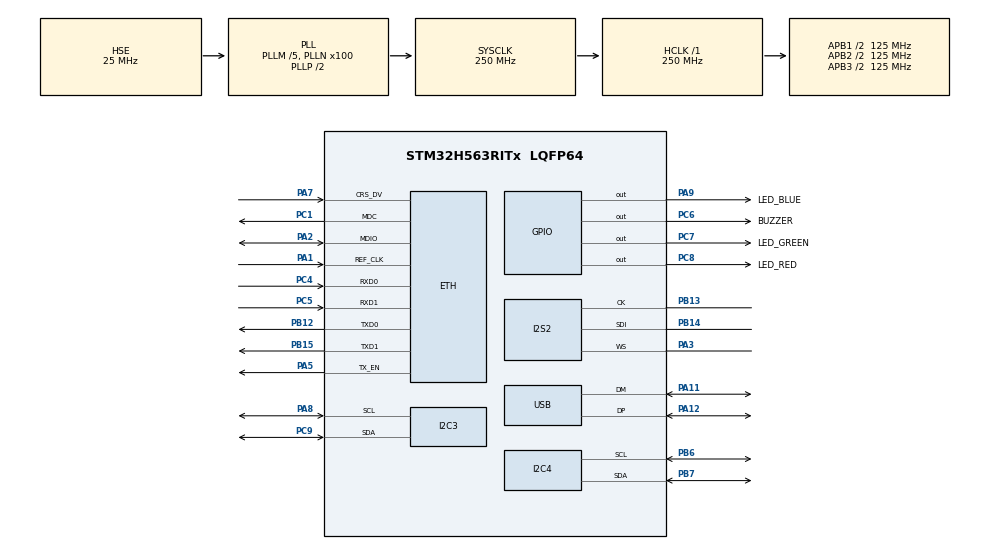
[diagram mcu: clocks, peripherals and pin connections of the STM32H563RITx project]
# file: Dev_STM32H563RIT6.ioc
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BOOTPATH.BootPathName=LEGACY
BOOTPATH.UserSelectedBootPath=LEGACY
CORTEX_M33_NS.userName=CORTEX_M33
ETH.MediaInterface=HAL_ETH_RMII_MODE
GPDMA1.CIRCULARMODE_GPDMACH0=ENABLE
GPDMA1.DESTDATAWIDTH_GPDMACH0=DMA_DEST_DATAWIDTH_HALFWORD
GPDMA1.DESTINC_GPDMACH0=DMA_DINC_INCREMENTED
GPDMA1.IPHANDLE_GPDMACH0-SIMPLEREQUEST_GPDMACH0=__NULL
GPDMA1.REQUEST_GPDMACH0=GPDMA1_REQUEST_SPI2_RX
GPDMA1.SRCDATAWIDTH_GPDMACH0=DMA_SRC_DATAWIDTH_HALFWORD
GPDMA1.SRCINC_GPDMACH0=DMA_SINC_FIXED
GPDMA1.TRANSFERALLOCATEDPORTDEST_GPDMACH0=DMA_DEST_ALLOCATED_PORT1
I2C3.Timing=0x20A0A3F6
I2C4.Timing=0x20A0A3F6
I2S2.AudioFreq=I2S_AUDIOFREQ_32K
I2S2.DataFormat=I2S_DATAFORMAT_16B_EXTENDED
I2S2.ErrorAudioFreq=0.05 %
I2S2.Instance=SPI$Index
I2S2.RealAudioFreq=32.018 KHz
Mcu.Family=STM32H5
Mcu.Name=STM32H563RITx
Mcu.Package=LQFP64
NETXDUO.ETH_ON=1
NETXDUO.LAN_8742=1
NETXDUO.NX_APP_MEM_POOL_SIZE=1024*100
NETXDUO.NX_APP_THREAD_STACK_SIZE=1024*4
NETXDUO.NX_DISABLE_UDP_TX_CHECKSUM=false
NETXDUO.NetXDuo_Application_Thread_Name=nx_UDP_thread_entry
NETXDUO.NetXDuo_Generate_Init_Code=true
NETXDUO.NetXDuo_Static_IP_address=192.168.1.111
NVIC.ETH_IRQn=true\:0\:0\:false\:false\:true\:false\:true\:true\:true
NVIC.GPDMA1_Channel0_IRQn=true\:0\:0\:false\:false\:true\:false\:false\:true\:true
NVIC.PriorityGroup=NVIC_PRIORITYGROUP_4
NVIC.TIM6_IRQn=true\:15\:0\:false\:false\:true\:false\:false\:true\:true
NVIC.TimeBase=TIM6_IRQn
NVIC.TimeBaseIP=TIM6
NetXDuo.BSP.number=1
NetXDuo0.BSP.STBoard=false
NetXDuo0.BSP.api=BSP_COMPONENT_DRIVER
NetXDuo0.BSP.component=lan8742
NetXDuo0.BSP.instance=lan8742
NetXDuo0.BSP.name=LAN_Component
NetXDuo0.BSP.semaphore=SEMA_lan8742
NetXDuo0.BSP.solution=lan8742
PA1.GPIO_Speed_Default_HIGH=GPIO_SPEED_FREQ_VERY_HIGH
PA1.Mode=RMII
PA1.Signal=ETH_REF_CLK
PA11.Mode=Device
PA11.Signal=USB_DM
PA12.Mode=Device
PA12.Signal=USB_DP
PA13(JTMS/SWDIO).Mode=Serial_Wire
PA13(JTMS/SWDIO).Signal=DEBUG_JTMS-SWDIO
PA14(JTCK/SWCLK).Mode=Serial_Wire
PA14(JTCK/SWCLK).Signal=DEBUG_JTCK-SWCLK
PA2.GPIO_Speed_Default_HIGH=GPIO_SPEED_FREQ_VERY_HIGH
PA2.Mode=RMII
PA2.Signal=ETH_MDIO
PA3.GPIO_Speed=GPIO_SPEED_FREQ_VERY_HIGH
PA3.Mode=Half_Duplex_Master_Rx
PA3.Signal=I2S2_WS
PA5.GPIO_Speed_Default_HIGH=GPIO_SPEED_FREQ_VERY_HIGH
PA5.Mode=RMII
PA5.Signal=ETH_TX_EN
PA7.GPIO_Speed_Default_HIGH=GPIO_SPEED_FREQ_VERY_HIGH
PA7.Mode=RMII
PA7.Signal=ETH_CRS_DV
PA8.Mode=I2C
PA8.Signal=I2C3_SCL
PA9.GPIO_Label=LED_BLUE
PA9.Signal=GPIO_Output
PB12.GPIO_Speed_Default_HIGH=GPIO_SPEED_FREQ_VERY_HIGH
PB12.Mode=RMII
PB12.Signal=ETH_TXD0
PB13.GPIO_Speed=GPIO_SPEED_FREQ_VERY_HIGH
PB13.Mode=Half_Duplex_Master_Rx
PB13.Signal=I2S2_CK
PB14.GPIO_Speed=GPIO_SPEED_FREQ_VERY_HIGH
PB14.Mode=Half_Duplex_Master_Rx
PB14.Signal=I2S2_SDI
PB15.GPIO_Speed_Default_HIGH=GPIO_SPEED_FREQ_VERY_HIGH
PB15.Mode=RMII
PB15.Signal=ETH_TXD1
PB6.Mode=I2C
PB6.Signal=I2C4_SCL
PB7.Mode=I2C
PB7.Signal=I2C4_SDA
PC1.GPIO_Speed_Default_HIGH=GPIO_SPEED_FREQ_VERY_HIGH
PC1.Mode=RMII
PC1.Signal=ETH_MDC
PC4.GPIO_Speed_Default_HIGH=GPIO_SPEED_FREQ_VERY_HIGH
PC4.Mode=RMII
PC4.Signal=ETH_RXD0
PC5.GPIO_Speed_Default_HIGH=GPIO_SPEED_FREQ_VERY_HIGH
PC5.Mode=RMII
PC5.Signal=ETH_RXD1
PC6.GPIO_Label=BUZZER
PC6.Signal=GPIO_Output
PC7.GPIO_Label=LED_GREEN
PC7.Signal=GPIO_Output
PC8.GPIO_Label=LED_RED
PC8.Signal=GPIO_Output
PC9.Mode=I2C
PC9.Signal=I2C3_SDA
PH0-OSC_IN(PH0).Mode=HSE-External-Oscillator
PH0-OSC_IN(PH0).Signal=RCC_OSC_IN
PH1-OSC_OUT(PH1).Mode=HSE-External-Oscillator
PH1-OSC_OUT(PH1).Signal=RCC_OSC_OUT
ProjectManager.HeapSize=0x200
ProjectManager.StackSize=0x400
ProjectManager.TargetToolchain=CMake
RCC.ADCFreq_Value=250000000
RCC.AHBFreq_Value=250000000
RCC.APB1CLKDivider=RCC_HCLK_DIV2
RCC.APB1Freq_Value=125000000
RCC.APB1TimFreq_Value=250000000
RCC.APB2CLKDivider=RCC_HCLK_DIV2
RCC.APB2Freq_Value=125000000
RCC.APB2TimFreq_Value=250000000
RCC.APB3CLKDivider=RCC_HCLK_DIV2
RCC.APB3Freq_Value=125000000
RCC.CSI_VALUE=4000000
RCC.CortexFreq_Value=250000000
RCC.EPOD_VALUE=25000000
RCC.HCLKFreq_Value=250000000
RCC.HSE_VALUE=25000000
RCC.HSI48_VALUE=48000000
RCC.HSI_VALUE=64000000
RCC.LSE_VALUE=32768
RCC.LSIRC_VALUE=32000
RCC.PLLM=5
RCC.PLLN=100
RCC.PLLSourceVirtual=RCC_PLL1_SOURCE_HSE
RCC.SYSCLKFreq_VALUE=250000000
RCC.SYSCLKSource=RCC_SYSCLKSOURCE_PLLCLK
RCC.USBFreq_Value=48000000
RCC.VCOOutputFreq_Value=500000000
THREADX.TX_APP_CREATION=1
THREADX.TX_APP_GENERATE_INIT_CODE=true
THREADX.TX_APP_MEM_POOL_SIZE=1024*20
THREADX.TX_APP_STACK_SIZE=1024*10
THREADX.TX_APP_THREAD_ENTRY=tx_I2C_thread_entry
THREADX.TX_APP_THREAD_NAME=tx I2C thread
USB.VirtualMode=Device_Only
VP_BOOTPATH_VS_BOOTPATH.Mode=BP_Activate
VP_CORTEX_M33_NS_VS_Hclk.Mode=Hclk_Mode
VP_GPDMA1_VS_GPDMACH0.Mode=SIMPLEREQUEST_GPDMACH0
VP_ICACHE_VS_ICACHE.Mode=DirectMappedCache
VP_MEMORYMAP_VS_MEMORYMAP.Mode=CurAppReg
VP_NETXDUO_VS_EthernetOoPhyOoInterface.Mode=LAN8742_Phy_Interface
VP_NETXDUO_VS_NXOoCore.Mode=NX_Core
VP_NETXDUO_VS_NetworkOoInterface.Mode=Ethernet_Interface
VP_PWR_VS_DBSignals.Mode=DisableDeadBatterySignals
VP_PWR_VS_LPOM.Mode=PowerOptimisation
VP_PWR_VS_SECSignals.Mode=Security/Privilege
VP_SYS_VS_tim6.Mode=TIM6
VP_THREADX_VS_RTOSJjThreadXJjCoreJjDefault.Mode=Core_Default
board=custom

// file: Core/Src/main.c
/* USER CODE BEGIN Header */
/**
  ******************************************************************************
  * @file           : main.c
  * @brief          : Main program body
  ******************************************************************************
  * @attention
  *
  * Copyright (c) 2025 STMicroelectronics.
  * All rights reserved.
  *
  * This software is licensed under terms that can be found in the LICENSE file
  * in the root directory of this software component.
  * If no LICENSE file comes with this software, it is provided AS-IS.
  *
  ******************************************************************************
  */
/* USER CODE END Header */
#include "app_threadx.h"
#include "main.h"
#include "string.h"

/* USER CODE BEGIN Includes */
#include <stdio.h>
#include "app_netxduo.h"
#include "string.h"
/* USER CODE END Includes */

/* USER CODE BEGIN PTD */
//extern void blink_blue(void);
/* USER CODE END PTD */

ETH_DMADescTypeDef  DMARxDscrTab[ETH_RX_DESC_CNT]; /* Ethernet Rx DMA Descriptors */
ETH_DMADescTypeDef  DMATxDscrTab[ETH_TX_DESC_CNT]; /* Ethernet Tx DMA Descriptors */

ETH_HandleTypeDef heth;

I2C_HandleTypeDef hi2c3;
I2C_HandleTypeDef hi2c4;

I2S_HandleTypeDef hi2s2;
DMA_NodeTypeDef Node_GPDMA1_Channel0;
DMA_QListTypeDef List_GPDMA1_Channel0;
DMA_HandleTypeDef handle_GPDMA1_Channel0;

PCD_HandleTypeDef hpcd_USB_DRD_FS;

void SystemClock_Config(void);
static void MX_GPIO_Init(void);
static void MX_GPDMA1_Init(void);
static void MX_ETH_Init(void);
static void MX_I2C3_Init(void);
static void MX_I2C4_Init(void);
static void MX_I2S2_Init(void);
static void MX_ICACHE_Init(void);
static void MX_USB_PCD_Init(void);

int main(void)
{

  /* MCU Configuration--------------------------------------------------------*/

  /* Reset of all peripherals, Initializes the Flash interface and the Systick. */
  HAL_Init();

  /* Configure the system clock */
  SystemClock_Config();

  /* Initialize all configured peripherals */
  MX_GPIO_Init();
  MX_GPDMA1_Init();
  MX_ETH_Init();
  MX_I2C3_Init();
  MX_I2C4_Init();
  MX_I2S2_Init();
  MX_ICACHE_Init();
  MX_USB_PCD_Init();

  MX_ThreadX_Init();

  /* We should never get here as control is now taken by the scheduler */

  /* Infinite loop */
  while (1)
  {

  }
}

void SystemClock_Config(void)
{
  RCC_OscInitTypeDef RCC_OscInitStruct = {0};
  RCC_ClkInitTypeDef RCC_ClkInitStruct = {0};

  /** Configure the main internal regulator output voltage
  */
  __HAL_PWR_VOLTAGESCALING_CONFIG(PWR_REGULATOR_VOLTAGE_SCALE0);

  while(!__HAL_PWR_GET_FLAG(PWR_FLAG_VOSRDY)) {}

  /** Initializes the RCC Oscillators according to the specified parameters
  * in the RCC_OscInitTypeDef structure.
  */
  RCC_OscInitStruct.OscillatorType = RCC_OSCILLATORTYPE_HSI48|RCC_OSCILLATORTYPE_HSE;
  RCC_OscInitStruct.HSEState = RCC_HSE_ON;
  RCC_OscInitStruct.HSI48State = RCC_HSI48_ON;
  RCC_OscInitStruct.PLL.PLLState = RCC_PLL_ON;
  RCC_OscInitStruct.PLL.PLLSource = RCC_PLL1_SOURCE_HSE;
  RCC_OscInitStruct.PLL.PLLM = 5;
  RCC_OscInitStruct.PLL.PLLN = 100;
  RCC_OscInitStruct.PLL.PLLP = 2;
  RCC_OscInitStruct.PLL.PLLQ = 2;
  RCC_OscInitStruct.PLL.PLLR = 2;
  RCC_OscInitStruct.PLL.PLLRGE = RCC_PLL1_VCIRANGE_2;
  RCC_OscInitStruct.PLL.PLLVCOSEL = RCC_PLL1_VCORANGE_WIDE;
  RCC_OscInitStruct.PLL.PLLFRACN = 0;
  if (HAL_RCC_OscConfig(&RCC_OscInitStruct) != HAL_OK)
  {
    Error_Handler();
  }

  /** Initializes the CPU, AHB and APB buses clocks
  */
  RCC_ClkInitStruct.ClockType = RCC_CLOCKTYPE_HCLK|RCC_CLOCKTYPE_SYSCLK
                              |RCC_CLOCKTYPE_PCLK1|RCC_CLOCKTYPE_PCLK2
                              |RCC_CLOCKTYPE_PCLK3;
  RCC_ClkInitStruct.SYSCLKSource = RCC_SYSCLKSOURCE_PLLCLK;
  RCC_ClkInitStruct.AHBCLKDivider = RCC_SYSCLK_DIV1;
  RCC_ClkInitStruct.APB1CLKDivider = RCC_HCLK_DIV2;
  RCC_ClkInitStruct.APB2CLKDivider = RCC_HCLK_DIV2;
  RCC_ClkInitStruct.APB3CLKDivider = RCC_HCLK_DIV2;

  if (HAL_RCC_ClockConfig(&RCC_ClkInitStruct, FLASH_LATENCY_5) != HAL_OK)
  {
    Error_Handler();
  }

  /** Configure the programming delay
  */
  __HAL_FLASH_SET_PROGRAM_DELAY(FLASH_PROGRAMMING_DELAY_2);
}

static void MX_ETH_Init(void)
{

   static uint8_t MACAddr[6];

  /* USER CODE BEGIN ETH_Init 1 */
      // for(int i = 0;i < 5; i++){
      //   blink_blue();
      // }
  /* USER CODE END ETH_Init 1 */
  heth.Instance = ETH;
  MACAddr[0] = 0x00;
  MACAddr[1] = 0x80;
  MACAddr[2] = 0xE1;
  MACAddr[3] = 0x00;
  MACAddr[4] = 0x00;
  MACAddr[5] = 0x00;
  heth.Init.MACAddr = &MACAddr[0];
  heth.Init.MediaInterface = HAL_ETH_RMII_MODE;
  heth.Init.TxDesc = DMATxDscrTab;
  heth.Init.RxDesc = DMARxDscrTab;
  heth.Init.RxBuffLen = 1524;

  if (HAL_ETH_Init(&heth) != HAL_OK)
  {
    Error_Handler();
  }

}

static void MX_GPDMA1_Init(void)
{

  /* Peripheral clock enable */
  __HAL_RCC_GPDMA1_CLK_ENABLE();

  /* GPDMA1 interrupt Init */
    HAL_NVIC_SetPriority(GPDMA1_Channel0_IRQn, 0, 0);
    HAL_NVIC_EnableIRQ(GPDMA1_Channel0_IRQn);

}

static void MX_I2C3_Init(void)
{

  hi2c3.Instance = I2C3;
  hi2c3.Init.Timing = 0x20A0A3F6;
  hi2c3.Init.OwnAddress1 = 0;
  hi2c3.Init.AddressingMode = I2C_ADDRESSINGMODE_7BIT;
  hi2c3.Init.DualAddressMode = I2C_DUALADDRESS_DISABLE;
  hi2c3.Init.OwnAddress2 = 0;
  hi2c3.Init.OwnAddress2Masks = I2C_OA2_NOMASK;
  hi2c3.Init.GeneralCallMode = I2C_GENERALCALL_DISABLE;
  hi2c3.Init.NoStretchMode = I2C_NOSTRETCH_DISABLE;
  if (HAL_I2C_Init(&hi2c3) != HAL_OK)
  {
    Error_Handler();
  }

  /** Configure Analogue filter
  */
  if (HAL_I2CEx_ConfigAnalogFilter(&hi2c3, I2C_ANALOGFILTER_ENABLE) != HAL_OK)
  {
    Error_Handler();
  }

  /** Configure Digital filter
  */
  if (HAL_I2CEx_ConfigDigitalFilter(&hi2c3, 0) != HAL_OK)
  {
    Error_Handler();
  }

}

static void MX_I2C4_Init(void)
{

  hi2c4.Instance = I2C4;
  hi2c4.Init.Timing = 0x20A0A3F6;
  hi2c4.Init.OwnAddress1 = 0;
  hi2c4.Init.AddressingMode = I2C_ADDRESSINGMODE_7BIT;
  hi2c4.Init.DualAddressMode = I2C_DUALADDRESS_DISABLE;
  hi2c4.Init.OwnAddress2 = 0;
  hi2c4.Init.OwnAddress2Masks = I2C_OA2_NOMASK;
  hi2c4.Init.GeneralCallMode = I2C_GENERALCALL_DISABLE;
  hi2c4.Init.NoStretchMode = I2C_NOSTRETCH_DISABLE;
  if (HAL_I2C_Init(&hi2c4) != HAL_OK)
  {
    Error_Handler();
  }

  /** Configure Analogue filter
  */
  if (HAL_I2CEx_ConfigAnalogFilter(&hi2c4, I2C_ANALOGFILTER_ENABLE) != HAL_OK)
  {
    Error_Handler();
  }

  /** Configure Digital filter
  */
  if (HAL_I2CEx_ConfigDigitalFilter(&hi2c4, 0) != HAL_OK)
  {
    Error_Handler();
  }

}

static void MX_I2S2_Init(void)
{

  hi2s2.Instance = SPI2;
  hi2s2.Init.Mode = I2S_MODE_MASTER_RX;
  hi2s2.Init.Standard = I2S_STANDARD_PHILIPS;
  hi2s2.Init.DataFormat = I2S_DATAFORMAT_16B_EXTENDED;
  hi2s2.Init.MCLKOutput = I2S_MCLKOUTPUT_DISABLE;
  hi2s2.Init.AudioFreq = I2S_AUDIOFREQ_32K;
  hi2s2.Init.CPOL = I2S_CPOL_LOW;
  hi2s2.Init.FirstBit = I2S_FIRSTBIT_MSB;
  hi2s2.Init.WSInversion = I2S_WS_INVERSION_DISABLE;
  hi2s2.Init.Data24BitAlignment = I2S_DATA_24BIT_ALIGNMENT_RIGHT;
  hi2s2.Init.MasterKeepIOState = I2S_MASTER_KEEP_IO_STATE_DISABLE;
  if (HAL_I2S_Init(&hi2s2) != HAL_OK)
  {
    Error_Handler();
  }

}

static void MX_ICACHE_Init(void)
{

  /** Enable instruction cache in 1-way (direct mapped cache)
  */
  if (HAL_ICACHE_ConfigAssociativityMode(ICACHE_1WAY) != HAL_OK)
  {
    Error_Handler();
  }
  if (HAL_ICACHE_Enable() != HAL_OK)
  {
    Error_Handler();
  }

}

static void MX_USB_PCD_Init(void)
{

  hpcd_USB_DRD_FS.Instance = USB_DRD_FS;
  hpcd_USB_DRD_FS.Init.dev_endpoints = 8;
  hpcd_USB_DRD_FS.Init.speed = USBD_FS_SPEED;
  hpcd_USB_DRD_FS.Init.phy_itface = PCD_PHY_EMBEDDED;
  hpcd_USB_DRD_FS.Init.Sof_enable = DISABLE;
  hpcd_USB_DRD_FS.Init.low_power_enable = DISABLE;
  hpcd_USB_DRD_FS.Init.lpm_enable = DISABLE;
  hpcd_USB_DRD_FS.Init.battery_charging_enable = DISABLE;
  hpcd_USB_DRD_FS.Init.vbus_sensing_enable = DISABLE;
  hpcd_USB_DRD_FS.Init.bulk_doublebuffer_enable = DISABLE;
  hpcd_USB_DRD_FS.Init.iso_singlebuffer_enable = DISABLE;
  if (HAL_PCD_Init(&hpcd_USB_DRD_FS) != HAL_OK)
  {
    Error_Handler();
  }

}

static void MX_GPIO_Init(void)
{
  GPIO_InitTypeDef GPIO_InitStruct = {0};

  /* GPIO Ports Clock Enable */
  __HAL_RCC_GPIOH_CLK_ENABLE();
  __HAL_RCC_GPIOC_CLK_ENABLE();
  __HAL_RCC_GPIOA_CLK_ENABLE();
  __HAL_RCC_GPIOB_CLK_ENABLE();

  /*Configure GPIO pin Output Level */
  HAL_GPIO_WritePin(GPIOC, BUZZER_Pin|LED_GREEN_Pin|LED_RED_Pin, GPIO_PIN_RESET);

  /*Configure GPIO pin Output Level */
  HAL_GPIO_WritePin(LED_BLUE_GPIO_Port, LED_BLUE_Pin, GPIO_PIN_RESET);

  /*Configure GPIO pins : BUZZER_Pin LED_GREEN_Pin LED_RED_Pin */
  GPIO_InitStruct.Pin = BUZZER_Pin|LED_GREEN_Pin|LED_RED_Pin;
  GPIO_InitStruct.Mode = GPIO_MODE_OUTPUT_PP;
  GPIO_InitStruct.Pull = GPIO_NOPULL;
  GPIO_InitStruct.Speed = GPIO_SPEED_FREQ_LOW;
  HAL_GPIO_Init(GPIOC, &GPIO_InitStruct);

  /*Configure GPIO pin : LED_BLUE_Pin */
  GPIO_InitStruct.Pin = LED_BLUE_Pin;
  GPIO_InitStruct.Mode = GPIO_MODE_OUTPUT_PP;
  GPIO_InitStruct.Pull = GPIO_NOPULL;
  GPIO_InitStruct.Speed = GPIO_SPEED_FREQ_LOW;
  HAL_GPIO_Init(LED_BLUE_GPIO_Port, &GPIO_InitStruct);

}

void HAL_TIM_PeriodElapsedCallback(TIM_HandleTypeDef *htim)
{
  if (htim->Instance == TIM6) {
    HAL_IncTick();
  }
}

void Error_Handler(void)
{
  __disable_irq();
  while (1)
  {
  }
}
